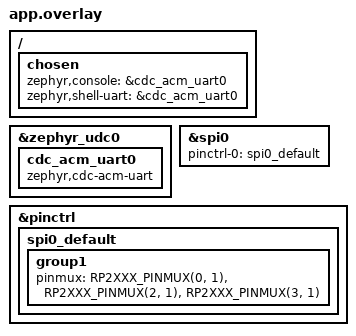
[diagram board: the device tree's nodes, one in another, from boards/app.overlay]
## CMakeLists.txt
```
cmake_minimum_required(VERSION 3.20)

set(EXTRA_ZEPHYR_MODULES "${CMAKE_CURRENT_SOURCE_DIR}/../../modules/rp2040_bootloader")

# set(DTC_OVERLAY_FILE "${CMAKE_CURRENT_SOURCE_DIR}/app.overlay")
# set(DTS_ROOT "${CMAKE_CURRENT_SOURCE_DIR}")

find_package(Zephyr REQUIRED HINTS $ENV{ZEPHYR_BASE})
project(my_cpp23_project)

# Use absolute pathing based on where this CMakeLists.txt lives
target_sources(app PRIVATE ${CMAKE_CURRENT_LIST_DIR}/src/main.cpp ${CMAKE_CURRENT_LIST_DIR}/src/blink.cpp)
target_include_directories(app PRIVATE ${CMAKE_CURRENT_LIST_DIR}/../../modules/rp2040_bootloader/include)

target_compile_features(app PUBLIC cxx_std_23)
```

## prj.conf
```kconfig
# Enable C++ Support
CONFIG_CPP=y
CONFIG_STD_CPP23=y
CONFIG_EXTERNAL_LIBCPP=y

# Use Newlib
CONFIG_NEWLIB_LIBC=y

# Generic Zephyr settings
CONFIG_GPIO=y
CONFIG_SPI=y

# Monitoring and stuff
CONFIG_USB_DEVICE_STACK=y
CONFIG_USB_DEVICE_INITIALIZE_AT_BOOT=y
CONFIG_SERIAL=y
CONFIG_CONSOLE=y
CONFIG_UART_CONSOLE=y
CONFIG_UART_LINE_CTRL=y

# Playground
CONFIG_SHELL=y
CONFIG_DEVICE_SHELL=y
CONFIG_UART_INTERRUPT_DRIVEN=y

# RP2040 Bootloader module
CONFIG_RP2040_BOOTLOADER=y
```

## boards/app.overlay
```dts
#include <zephyr/dt-bindings/pinctrl/rpi-pico-rp2040-pinctrl.h>

/ {
    chosen {
        zephyr,console = &cdc_acm_uart0;
        zephyr,shell-uart = &cdc_acm_uart0;
    };
};

&zephyr_udc0 {
    cdc_acm_uart0: cdc_acm_uart0 {
        compatible = "zephyr,cdc-acm-uart";
    };
};

&spi0 {
    status = "okay";
    pinctrl-0 = <&spi0_default>;
    pinctrl-names = "default";
};

&pinctrl {
    spi0_default: spi0_default {
        group1 {
            /*
             * Format: RP2XXX_PINMUX(pin, function)
             * Function 1 is SPI for RP2040
             */
            pinmux = <RP2XXX_PINMUX(0, 1)>, /* TX / MOSI */
                     <RP2XXX_PINMUX(2, 1)>, /* SCK */
                     <RP2XXX_PINMUX(3, 1)>; /* RX / MISO */
        };
    };
};
```

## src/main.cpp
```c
#include <zephyr/drivers/gpio.h>
#include <zephyr/kernel.h>
#include <zephyr/shell/shell.h>
#include "zephyr/sys/printk.h"

#include "bootloader_cmd.h"
#include "blink.hpp"

static int cmd_hello(const struct shell *sh, int argc, char **argv) {
  printk("World!\n");
  return 0;
}

SHELL_STATIC_SUBCMD_SET_CREATE(sub_demo,
        SHELL_CMD(ping, NULL, "Ping command.", +[](const struct shell *sh, int argc, char **argv) -> int {
            ARG_UNUSED(sh);
            ARG_UNUSED(argc);
            ARG_UNUSED(argv);

            printk("Pong!\n");
            return 0;
        }),
        SHELL_SUBCMD_SET_END
);

SHELL_CMD_REGISTER(hello, &sub_demo, "Print \"World!\"", cmd_hello);

int main(void) {
  const struct gpio_dt_spec led = GPIO_DT_SPEC_GET(DT_ALIAS(led0), gpios);

  if (blink_setup(led) != 0) {
    return -1;
  }

  static struct k_timer blink_timer;

  blink_timer_start(led, &blink_timer, K_SECONDS(1), K_SECONDS(1));

  while (true) {
    k_sleep(K_FOREVER);
  }

  (void)cmd_bootloader;
  return 0;
}
```

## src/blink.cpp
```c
#include "blink.hpp"

#include <errno.h>

namespace {
const gpio_dt_spec *g_led;

void timer_expiry(struct k_timer *timer) {
  ARG_UNUSED(timer);
  gpio_pin_toggle_dt(g_led);
}
}  // namespace

int blink_setup(const gpio_dt_spec &led) {
  if (!gpio_is_ready_dt(&led)) {
    return -ENODEV;
  }

  return gpio_pin_configure_dt(&led, GPIO_OUTPUT_ACTIVE);
}

int blink_once(const gpio_dt_spec &led, int interval_ms) {
  gpio_pin_toggle_dt(&led);
  k_msleep(interval_ms);
  gpio_pin_toggle_dt(&led);
  k_msleep(10);
  return 0;
}

void blink_timer_start(const gpio_dt_spec &led, struct k_timer *timer,
                       k_timeout_t delay, k_timeout_t period) {

  g_led = &led;
  k_timer_init(timer, timer_expiry, NULL);
  k_timer_start(timer, delay, period);
}
```

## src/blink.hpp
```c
#pragma once

#include <zephyr/drivers/gpio.h>
#include <zephyr/kernel.h>

int blink_setup(const gpio_dt_spec &led);

int blink_once(const gpio_dt_spec &led, int interval_ms);

void blink_timer_start(const gpio_dt_spec &led, struct k_timer *timer,
                       k_timeout_t delay, k_timeout_t period);
```
